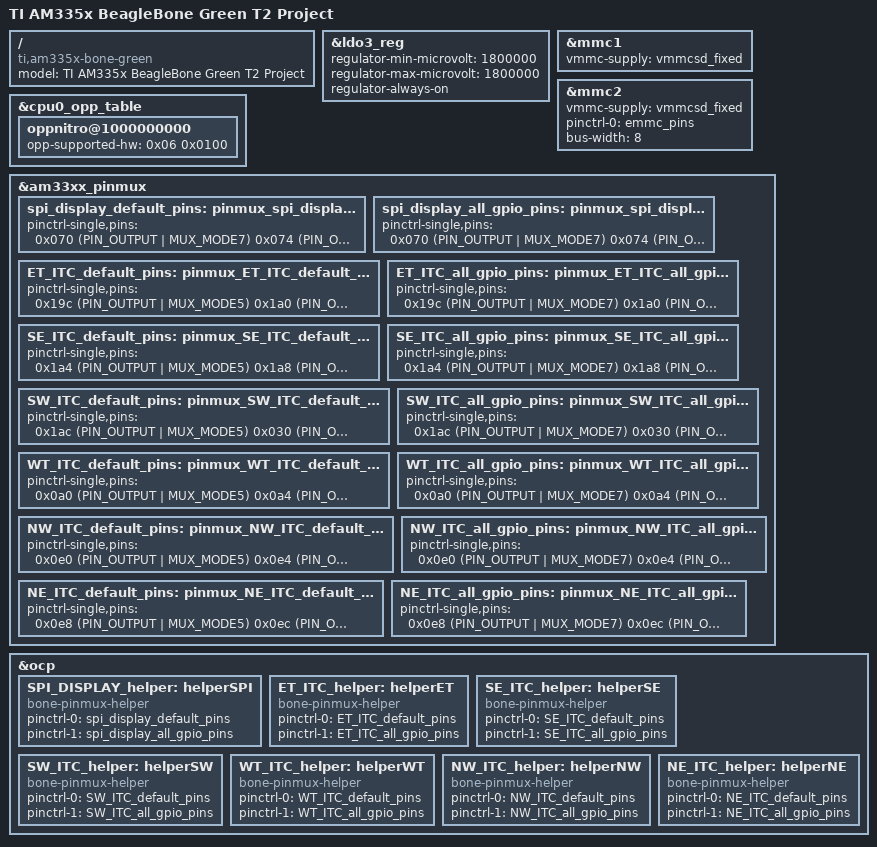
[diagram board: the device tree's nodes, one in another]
/*
 * Base device tree for BeagleBone Green as used in the T2 indefinitely scalable tile
 * 
 * Revisions Copyrignt (C) 2017 The Regents of the University of New Mexico
 * Author: Dave Ackley <ackley@ackleyshack.com>
 *
 * Based on am335x-bonegreen.dts, which is
 * Copyright (C) 2012 Texas Instruments Incorporated - http://www.ti.com/
 *
 * This program is free software; you can redistribute it and/or modify
 * it under the terms of the GNU General Public License version 2 as
 * published by the Free Software Foundation.
 */
/dts-v1/;

#include "am33xx.dtsi"
#include "am335x-bone-common.dtsi"

/* AHAX: 2017-05-19 PRUSS option: For now we are going with UIO.. */
#include "am33xx-pruss-uio.dtsi"

/ {
	model = "TI AM335x BeagleBone Green T2 Project";
	compatible = "ti,am335x-bone-green", "ti,am335x-bone-black", "ti,am335x-bone", "ti,am33xx";
};

&ldo3_reg {
	regulator-min-microvolt = <1800000>;
	regulator-max-microvolt = <1800000>;
	regulator-always-on;
};

&mmc1 {
	vmmc-supply = <&vmmcsd_fixed>;
};

&mmc2 {
	vmmc-supply = <&vmmcsd_fixed>;
	pinctrl-names = "default";
	pinctrl-0 = <&emmc_pins>;
	bus-width = <8>;
	status = "okay";
};

&cpu0_opp_table {
	/*
	 * All PG 2.0 silicon may not support 1GHz but some of the early
	 * BeagleBone Blacks have PG 2.0 silicon which is guaranteed
	 * to support 1GHz OPP so enable it for PG 2.0 on this board.
	 */
	oppnitro@1000000000 {
		opp-supported-hw = <0x06 0x0100>;
	};
};

/****************************************
* Pin Muxing
****************************************/
&am33xx_pinmux {
#if 0
	 // From ebb chp13 overlay sample dts
         pru_pru_pins: pinmux_pru_pru_pins {   // The PRU pin modes
            pinctrl-single,pins = <
               0x1a4 0x05  // P9_27 pr1_pru0_pru_r30_5, MODE5 | OUTPUT | PRU
               0x19c 0x26  // P9_28 pr1_pru0_pru_r31_3, MODE6 | INPUT | PRU
            >;
         };
#endif

	 // SPI DISPLAY SUPPORT VIA SPI0 HARDWARE
         spi_display_default_pins: pinmux_spi_display_default_pins {   
            pinctrl-single,pins = <
	       0x070 (PIN_OUTPUT | MUX_MODE7)        // P9_11  PINS=28  GPIO=30  T2=DSP_PWRON
	       0x074 (PIN_OUTPUT | MUX_MODE7)        // P9_13  PINS=29  GPIO=31  T2=DSP_RESET
	       0x040 (PIN_OUTPUT | MUX_MODE7)        // P9_15  PINS=16  GPIO=48  T2=DSP_DC
	       0x17c (PIN_INPUT_PULLUP | MUX_MODE7)  // P9_19  PINS=95  GPIO=13  T2=TP_IRQ
	       0x178 (PIN_OUTPUT | MUX_MODE7)        // P9_20  PINS=94  GPIO=12  T2=TP_CS
	       0x15c (PIN_OUTPUT | MUX_MODE0)        // P9_17  PINS=87  GPIO=5   T2=SPI0_CS
	       0x158 (PIN_INPUT_PULLUP | MUX_MODE0)  // P9_18  PINS=86  GPIO=4   T2=SPI0_D1
	       0x154 (PIN_OUTPUT | MUX_MODE0)        // P9_21  PINS=85  GPIO=3   T2=SPI0_D0
	       0x150 (PIN_OUTPUT | MUX_MODE0)        // P9_22  PINS=84  GPIO=2   T2=SPI0_SCLK
            >;
         };

	 // SPI DISPLAY SUPPORT ALL GPIOS FOR DEBUGGING
	 spi_display_all_gpio_pins: pinmux_spi_display_all_gpio_pins {   // GPIO pins for linux
            pinctrl-single,pins = <
	       0x070 (PIN_OUTPUT | MUX_MODE7)        // P9_11  PINS=28  GPIO=30  T2=DSP_PWRON
	       0x074 (PIN_OUTPUT | MUX_MODE7)        // P9_13  PINS=29  GPIO=31  T2=DSP_RESET
	       0x040 (PIN_OUTPUT | MUX_MODE7)        // P9_15  PINS=16  GPIO=48  T2=DSP_DC
	       0x17c (PIN_INPUT_PULLUP | MUX_MODE7)  // P9_19  PINS=95  GPIO=13  T2=TP_IRQ
	       0x178 (PIN_OUTPUT | MUX_MODE7)        // P9_20  PINS=94  GPIO=12  T2=TP_CS
	       0x15c (PIN_OUTPUT | MUX_MODE7)        // P9_17  PINS=87  GPIO=5   T2=SPI0_CS as gpio
	       0x158 (PIN_INPUT_PULLUP | MUX_MODE7)  // P9_18  PINS=86  GPIO=4   T2=SPI0_D1 as gpio
	       0x154 (PIN_OUTPUT | MUX_MODE7)        // P9_21  PINS=85  GPIO=3   T2=SPI0_D0 as gpio
	       0x150 (PIN_OUTPUT | MUX_MODE7)        // P9_22  PINS=84  GPIO=2   T2=SPI0_SCLK as gpio
            >;
         };

	 /////////////////
	 // T2 InterTile Connector (ITC) PIN MUXES
	 //
	 // NOTE: Conventional ITC iteration goes clockwise from east: ET,SE,SW,WT,NW,NE
	 // (though that doesn't matter explicitly in any of these .dts declarations).
	 //
	 // NOTE: We have no pullup/downs on any of the {ET,WT,NE,NW,SE,SW}_ITC signal 
	 // pins, because they all connect to line drivers with bus hold circuits.  We
	 // hope that's the right thing to do.

	 // ET_ITC default pins (split PRU/Linux gpio)
         ET_ITC_default_pins: pinmux_ET_ITC_default_pins {
            pinctrl-single,pins = <
               0x19c (PIN_OUTPUT | MUX_MODE5)  // P9_28  PINS=103 GPIO=113 T2=ET_TXRDY pr1_pru0_pru_r30_3
               0x1a0 (PIN_OUTPUT | MUX_MODE5)  // P9_42B PINS=104 GPIO=114 T2=ET_TXDAT pr1_pru0_pru_r30_4
               0x164 (PIN_INPUT  | MUX_MODE7)  // P9_42A PINS=89  GPIO=7   T2=RSRVINP2 (conflicts with ET_TXDAT, must be input)
               0x190 (PIN_INPUT  | MUX_MODE6)  // P9_31  PINS=100 GPIO=110 T2=ET_RXRDY pr1_pru0_pru_r31_0
               0x194 (PIN_INPUT  | MUX_MODE6)  // P9_29  PINS=101 GPIO=111 T2=ET_RXDAT pr1_pru0_pru_r31_1
               0x090 (PIN_OUTPUT | MUX_MODE7)  // P8_07  PINS=36  GPIO=66  T2=ET_ORQLK
               0x094 (PIN_OUTPUT | MUX_MODE7)  // P8_08  PINS=37  GPIO=67  T2=ET_OGRLK
               0x09c (PIN_INPUT  | MUX_MODE7)  // P8_09  PINS=39  GPIO=69  T2=ET_IRQLK
               0x098 (PIN_INPUT  | MUX_MODE7)  // P8_10  PINS=38  GPIO=68  T2=ET_IGRLK
            >;
         };

	 // ET_ITC all gpio pins (Linux gpio)
         ET_ITC_all_gpio_pins: pinmux_ET_ITC_all_gpio_pins {
            pinctrl-single,pins = <
               0x19c (PIN_OUTPUT | MUX_MODE7)  // P9_28  PINS=103 GPIO=113 T2=ET_TXRDY as gpio
               0x1a0 (PIN_OUTPUT | MUX_MODE7)  // P9_42B PINS=104 GPIO=114 T2=ET_TXDAT as gpio
               0x164 (PIN_INPUT  | MUX_MODE7)  // P9_42A PINS=89  GPIO=7   T2=RSRVINP2 (shares pin with ET_TXDAT, must be input)
               0x190 (PIN_INPUT  | MUX_MODE7)  // P9_31  PINS=100 GPIO=110 T2=ET_RXRDY as gpio
               0x194 (PIN_INPUT  | MUX_MODE7)  // P9_29  PINS=101 GPIO=111 T2=ET_RXDAT as gpio
               0x090 (PIN_OUTPUT | MUX_MODE7)  // P8_07  PINS=36  GPIO=66  T2=ET_ORQLK
               0x094 (PIN_OUTPUT | MUX_MODE7)  // P8_08  PINS=37  GPIO=67  T2=ET_OGRLK
               0x09c (PIN_INPUT  | MUX_MODE7)  // P8_09  PINS=39  GPIO=69  T2=ET_IRQLK
               0x098 (PIN_INPUT  | MUX_MODE7)  // P8_10  PINS=38  GPIO=68  T2=ET_IGRLK
            >;
         };


	 // SE_ITC default pins (split PRU/Linux gpio)
         SE_ITC_default_pins: pinmux_SE_ITC_default_pins {
            pinctrl-single,pins = <
               0x1a4 (PIN_OUTPUT | MUX_MODE5)  // P9_27  PINS=106 GPIO=115 T2=SE_TXRDY pr1_pru0_pru_r30_5
               0x1a8 (PIN_OUTPUT | MUX_MODE5)  // P9_41B PINS=?   GPIO=116 T2=SE_TXDAT pr1_pru0_pru_r30_6
               0x1b4 (PIN_INPUT  | MUX_MODE7)  // P9_41A PINS=109 GPIO=20  T2=RSRVINP1 (shares pin with SE_TXDAT, must be input)
               0x198 (PIN_INPUT  | MUX_MODE6)  // P9_30  PINS=102 GPIO=112 T2=SE_RXRDY pr1_pru0_pru_r31_2
               0x038 (PIN_INPUT  | MUX_MODE6)  // P8_16  PINS=43  GPIO=14  T2=SE_RXDAT pr1_pru0_pru_r31_14
               0x034 (PIN_OUTPUT | MUX_MODE7)  // P8_11  PINS=13  GPIO=45  T2=SE_ORQLK
               0x024 (PIN_OUTPUT | MUX_MODE7)  // P8_13  PINS=9   GPIO=23  T2=SE_OGRLK
               0x028 (PIN_INPUT  | MUX_MODE7)  // P8_14  PINS=10  GPIO=26  T2=SE_IRQLK
               0x02c (PIN_INPUT  | MUX_MODE7)  // P8_17  PINS=11  GPIO=27  T2=SE_IGRLK
            >;
         };

	 // SE_ITC all gpio pins (Linux gpio)
         SE_ITC_all_gpio_pins: pinmux_SE_ITC_all_gpio_pins {
            pinctrl-single,pins = <
               0x1a4 (PIN_OUTPUT | MUX_MODE7)  // P9_27  PINS=106 GPIO=115 T2=SE_TXRDY as gpio
               0x1a8 (PIN_OUTPUT | MUX_MODE7)  // P9_41B PINS=?   GPIO=116 T2=SE_TXDAT as gpio
               0x1b4 (PIN_INPUT  | MUX_MODE7)  // P9_41A PINS=109 GPIO=20  T2=RSRVINP1 (shares pin with SE_TXDAT, must be input)
               0x198 (PIN_INPUT  | MUX_MODE7)  // P9_30  PINS=102 GPIO=112 T2=SE_RXRDY as gpio
               0x038 (PIN_INPUT  | MUX_MODE7)  // P8_16  PINS=43  GPIO=14  T2=SE_RXDAT as gpio
               0x034 (PIN_OUTPUT | MUX_MODE7)  // P8_11  PINS=13  GPIO=45  T2=SE_ORQLK
               0x024 (PIN_OUTPUT | MUX_MODE7)  // P8_13  PINS=9   GPIO=23  T2=SE_OGRLK
               0x028 (PIN_INPUT  | MUX_MODE7)  // P8_14  PINS=10  GPIO=26  T2=SE_IRQLK
               0x02c (PIN_INPUT  | MUX_MODE7)  // P8_17  PINS=11  GPIO=27  T2=SE_IGRLK
            >;
         };

	 // SW_ITC default pins (split PRU/Linux gpio)
         SW_ITC_default_pins: pinmux_SW_ITC_default_pins {
            pinctrl-single,pins = <
               0x1ac (PIN_OUTPUT | MUX_MODE5)  // P9_25  PINS=107 GPIO=117 T2=SW_TXRDY pr1_pru0_pru_r30_7
               0x030 (PIN_OUTPUT | MUX_MODE5)  // P8_12  PINS=12  GPIO=44  T2=SW_TXDAT pr1_pru0_pru_r30_14
               0x03c (PIN_INPUT  | MUX_MODE6)  // P8_15  PINS=15  GPIO=47  T2=SW_RXRDY pr1_pru0_pru_r31_15
               0x184 (PIN_INPUT  | MUX_MODE6)  // P9_24  PINS=96  GPIO=15  T2=SW_RXDAT pr1_pru0_pru_r31_16
               0x08c (PIN_OUTPUT | MUX_MODE7)  // P8_18  PINS=35  GPIO=65  T2=SW_ORQLK
               0x024 (PIN_OUTPUT | MUX_MODE7)  // P8_19  PINS=8   GPIO=22  T2=SW_OGRLK
               0x07c (PIN_INPUT  | MUX_MODE7)  // P8_26  PINS=31  GPIO=61  T2=SW_IRQLK
               0x0d8 (PIN_INPUT  | MUX_MODE7)  // P8_31  PINS=54  GPIO=10  T2=SW_IGRLK
            >;
         };

	 // SW_ITC all gpio pins (Linux gpio)
         SW_ITC_all_gpio_pins: pinmux_SW_ITC_all_gpio_pins {
            pinctrl-single,pins = <
               0x1ac (PIN_OUTPUT | MUX_MODE7)  // P9_25  PINS=107 GPIO=117 T2=SW_TXRDY as gpio
               0x030 (PIN_OUTPUT | MUX_MODE7)  // P8_12  PINS=12  GPIO=44  T2=SW_TXDAT as gpio
               0x03c (PIN_INPUT  | MUX_MODE7)  // P8_15  PINS=15  GPIO=47  T2=SW_RXRDY as gpio
               0x184 (PIN_INPUT  | MUX_MODE7)  // P9_24  PINS=96  GPIO=15  T2=SW_RXDAT as gpio
               0x08c (PIN_OUTPUT | MUX_MODE7)  // P8_18  PINS=35  GPIO=65  T2=SW_ORQLK
               0x024 (PIN_OUTPUT | MUX_MODE7)  // P8_19  PINS=8   GPIO=22  T2=SW_OGRLK
               0x07c (PIN_INPUT  | MUX_MODE7)  // P8_26  PINS=31  GPIO=61  T2=SW_IRQLK
               0x0d8 (PIN_INPUT  | MUX_MODE7)  // P8_31  PINS=54  GPIO=10  T2=SW_IGRLK
            >;
         };

	 // WT_ITC default pins (split PRU/Linux gpio)
         WT_ITC_default_pins: pinmux_WT_ITC_default_pins {
            pinctrl-single,pins = <
               0x0a0 (PIN_OUTPUT | MUX_MODE5)  // P8_45  PINS=40  GPIO=70  T2=WT_TXRDY pr1_pru1_pru_r30_0
               0x0a4 (PIN_OUTPUT | MUX_MODE5)  // P8_46  PINS=41  GPIO=71  T2=WT_TXDAT pr1_pru1_pru_r30_1
               0x0b8 (PIN_INPUT  | MUX_MODE6)  // P8_39  PINS=46  GPIO=76  T2=WT_RXRDY pr1_pru1_pru_r31_6
               0x0bc (PIN_INPUT  | MUX_MODE6)  // P8_40  PINS=47  GPIO=77  T2=WT_RXDAT pr1_pru1_pru_r31_7
               0x0dc (PIN_OUTPUT | MUX_MODE7)  // P8_32  PINS=55  GPIO=11  T2=WT_ORQLK
               0x0d4 (PIN_OUTPUT | MUX_MODE7)  // P8_33  PINS=53  GPIO=9   T2=WT_OGRLK
               0x0cc (PIN_INPUT  | MUX_MODE7)  // P8_34  PINS=51  GPIO=81  T2=WT_IRQLK
               0x0d0 (PIN_INPUT  | MUX_MODE7)  // P8_35  PINS=52  GPIO=8   T2=WT_IGRLK
            >;
         };

	 // WT_ITC all gpio pins (Linux gpio)
         WT_ITC_all_gpio_pins: pinmux_WT_ITC_all_gpio_pins {
            pinctrl-single,pins = <
               0x0a0 (PIN_OUTPUT | MUX_MODE7)  // P8_45  PINS=40  GPIO=70  T2=WT_TXRDY as gpio
               0x0a4 (PIN_OUTPUT | MUX_MODE7)  // P8_46  PINS=41  GPIO=71  T2=WT_TXDAT as gpio
               0x0b8 (PIN_INPUT  | MUX_MODE7)  // P8_39  PINS=46  GPIO=76  T2=WT_RXRDY as gpio
               0x0bc (PIN_INPUT  | MUX_MODE7)  // P8_40  PINS=47  GPIO=77  T2=WT_RXDAT as gpio
               0x0dc (PIN_OUTPUT | MUX_MODE7)  // P8_32  PINS=55  GPIO=11  T2=WT_ORQLK
               0x0d4 (PIN_OUTPUT | MUX_MODE7)  // P8_33  PINS=53  GPIO=9   T2=WT_OGRLK
               0x0cc (PIN_INPUT  | MUX_MODE7)  // P8_34  PINS=51  GPIO=81  T2=WT_IRQLK
               0x0d0 (PIN_INPUT  | MUX_MODE7)  // P8_35  PINS=52  GPIO=8   T2=WT_IGRLK
            >;
         };

	 // NW_ITC default pins (split PRU/Linux gpio)
         NW_ITC_default_pins: pinmux_NW_ITC_default_pins {
            pinctrl-single,pins = <
               0x0e0 (PIN_OUTPUT | MUX_MODE5)  // P8_27  PINS=56  GPIO=86  T2=NW_TXRDY pr1_pru1_pru_r30_8
               0x0e4 (PIN_OUTPUT | MUX_MODE5)  // P8_39  PINS=57  GPIO=87  T2=NW_TXDAT pr1_pru1_pru_r30_9
               0x0a8 (PIN_INPUT  | MUX_MODE6)  // P8_43  PINS=42  GPIO=72  T2=NW_RXRDY pr1_pru1_pru_r31_2
               0x1ac (PIN_INPUT  | MUX_MODE6)  // P8_44  PINS=43  GPIO=73  T2=NW_RXDAT pr1_pru1_pru_r31_3
               0x0c8 (PIN_OUTPUT | MUX_MODE7)  // P8_36  PINS=50  GPIO=80  T2=NW_ORQLK
               0x0c0 (PIN_OUTPUT | MUX_MODE7)  // P8_37  PINS=48  GPIO=78  T2=NW_OGRLK
               0x0c4 (PIN_INPUT  | MUX_MODE7)  // P8_38  PINS=49  GPIO=79  T2=NW_IRQLK
               0x078 (PIN_INPUT  | MUX_MODE7)  // P9_12  PINS=30  GPIO=60  T2=NW_IGRLK
            >;
         };

	 // NW_ITC all gpio pins (Linux gpio)
         NW_ITC_all_gpio_pins: pinmux_NW_ITC_all_gpio_pins {
            pinctrl-single,pins = <
               0x0e0 (PIN_OUTPUT | MUX_MODE7)  // P8_27  PINS=56  GPIO=86  T2=NW_TXRDY as gpio
               0x0e4 (PIN_OUTPUT | MUX_MODE7)  // P8_39  PINS=57  GPIO=87  T2=NW_TXDAT as gpio
               0x0a8 (PIN_INPUT  | MUX_MODE7)  // P8_43  PINS=42  GPIO=72  T2=NW_RXRDY as gpio
               0x1ac (PIN_INPUT  | MUX_MODE7)  // P8_44  PINS=43  GPIO=73  T2=NW_RXDAT as gpio
               0x0c8 (PIN_OUTPUT | MUX_MODE7)  // P8_36  PINS=50  GPIO=80  T2=NW_ORQLK
               0x0c0 (PIN_OUTPUT | MUX_MODE7)  // P8_37  PINS=48  GPIO=78  T2=NW_OGRLK
               0x0c4 (PIN_INPUT  | MUX_MODE7)  // P8_38  PINS=49  GPIO=79  T2=NW_IRQLK
               0x078 (PIN_INPUT  | MUX_MODE7)  // P9_12  PINS=30  GPIO=60  T2=NW_IGRLK
            >;
         };

	 // NE_ITC default pins (split PRU/Linux gpio)
         NE_ITC_default_pins: pinmux_NE_ITC_default_pins {
            pinctrl-single,pins = <
               0x0e8 (PIN_OUTPUT | MUX_MODE5)  // P8_28  PINS=58  GPIO=88  T2=NE_TXRDY pr1_pru1_pru_r30_10
               0x0ec (PIN_OUTPUT | MUX_MODE5)  // P8_30  PINS=59  GPIO=89  T2=NE_TXDAT pr1_pru1_pru_r30_11
               0x0b0 (PIN_INPUT  | MUX_MODE6)  // P8_41  PINS=44  GPIO=74  T2=NE_RXRDY pr1_pru1_pru_r31_4
               0x0b4 (PIN_INPUT  | MUX_MODE6)  // P8_42  PINS=45  GPIO=75  T2=NE_RXDAT pr1_pru1_pru_r31_5
               0x048 (PIN_OUTPUT | MUX_MODE7)  // P9_14  PINS=18  GPIO=50  T2=NE_ORQLK
               0x04c (PIN_OUTPUT | MUX_MODE7)  // P9_16  PINS=19  GPIO=51  T2=NE_OGRLK
               0x044 (PIN_INPUT  | MUX_MODE7)  // P9_23  PINS=17  GPIO=49  T2=NE_IRQLK
               0x180 (PIN_INPUT  | MUX_MODE7)  // P9_26  PINS=96  GPIO=14  T2=NE_IGRLK
            >;
         };

	 // NE_ITC all gpio pins (Linux gpio)
         NE_ITC_all_gpio_pins: pinmux_NE_ITC_all_gpio_pins {
            pinctrl-single,pins = <
               0x0e8 (PIN_OUTPUT | MUX_MODE7)  // P8_28  PINS=58  GPIO=88  T2=NE_TXRDY as gpio
               0x0ec (PIN_OUTPUT | MUX_MODE7)  // P8_30  PINS=59  GPIO=89  T2=NE_TXDAT as gpio
               0x0b0 (PIN_INPUT  | MUX_MODE7)  // P8_41  PINS=44  GPIO=74  T2=NE_RXRDY as gpio
               0x0b4 (PIN_INPUT  | MUX_MODE7)  // P8_42  PINS=45  GPIO=75  T2=NE_RXDAT as gpio
               0x048 (PIN_OUTPUT | MUX_MODE7)  // P9_14  PINS=18  GPIO=50  T2=NE_ORQLK
               0x04c (PIN_OUTPUT | MUX_MODE7)  // P9_16  PINS=19  GPIO=51  T2=NE_OGRLK
               0x044 (PIN_INPUT  | MUX_MODE7)  // P9_23  PINS=17  GPIO=49  T2=NE_IRQLK
               0x180 (PIN_INPUT  | MUX_MODE7)  // P9_26  PINS=96  GPIO=14  T2=NE_IGRLK
            >;
         };


// P9_11_default_pin: pinmux_P9_11_default_pin {
	// 	pinctrl-single,pins = <0x070  0x36>; };     /* Mode 6 uart */
	// P9_11_gpio_pin: pinmux_P9_11_gpio_pin {
	// 	pinctrl-single,pins = <0x070  0x2F>; };     /* Mode 7, RxActive */


	// A15_spi_pin: pinmux_A15_spi_pin {
	// 	pinctrl-single,pins = <
	// 		BLUE_IO(108, PIN_INPUT_PULLUP | MUX_MODE4) /* spi1_cs1 */
	// 	>;
	// };

	// mux_helper_pins: pins {
	// 	pinctrl-single,pins = <
	// 		/* PRU encoder input */
	// 		0x03c 0x36	/* P8_15,PRU0_r31_15,MODE6 */
	// 		0x038 0x36	/* P8_16,PRU0_r31_16,MODE6 */

	// 		/* PRU Servo output */
	// 		0x0e0 0x25	/*pru1_pru_r30_8, MODE5*/
	// 		0x0e8 0x25	/*pru1_pru_r30_10, MODE5 */
	// 		0x0e4 0x25	/*pr1_pru1_pru_r30_9, MODE5 */
	// 		0x0ec 0x25	/*pru1_pru_r30_11, MODE5 */
	// 		0x0b8 0x25	/*pru1_pru_r30_6, MODE5 */
	// 		0x0bc 0x25	/*pru1_pru_r30_7, MODE5 */
	// 		0x0b0 0x25	/*pru1_pru_r30_4, MODE5 */
	// 		0x0b4 0x25	/*pru1_pru_r30_5, MODE5 */

	// 		/* GPIO Inputs */
	// 		0x09c 0x37	/*P8.9  Pause BUTTON, input pullup*/
	// 		0x098 0x37	/*P8.10 MODE BUTTON input pullup*/
	// 		0x1AC 0x37	/*P9.25 MPU-9150 INTERRUPT IN*/

	// 		/* GPIO Outputs
	// 		0x090 0x0F	/*P8.7 - R7*/
	// 		0x094 0x0F	/*P8.8*/
	// 		0x028 0x0F	/*P8.14*/
	// 		0x02C 0x0F	/*P8.17*/
	// 		0x08c 0x0F	/*P8.18*/
	// 		0x07c 0x0F	/*P8.26*/
	// 		/* 0x0?? 0x0F	/*P8.32 - T5 - BATT_LED3 */
	// 		0x0cc 0x0F	/*P8.34*/
	// 		0x0C8 0x0F	/*P8.36*/
	// 		0x0a8 0x0F	/*P8.43*/
	// 		0x0ac 0x0F	/*P8.44*/
	// 		0x0a0 0x0F	/*P8.45*/
	// 		0x0a4 0x0F	/*P8.46*/
	// 		0x078 0x0F	/*P9.12*/
	// 		0x074 0x0F	/*P9.13*/
	// 		0x040 0x0F	/*P9.15*/
	// 		0x044 0x0F	/*P9.23*/
	// 		0x1b4 0x0F	/*P9.41*/
	// 	>;
	// };

	// /****************************************/
	// /* DSM2 UART4 pinmux                    */
	// /* only pin that swaps between GPIO&UART*/
	// /****************************************/
	// P9_11_default_pin: pinmux_P9_11_default_pin {
	// 	pinctrl-single,pins = <0x070  0x36>; };     /* Mode 6 uart */
	// P9_11_gpio_pin: pinmux_P9_11_gpio_pin {
	// 	pinctrl-single,pins = <0x070  0x2F>; };     /* Mode 7, RxActive */
	// P9_11_gpio_pu_pin: pinmux_P9_11_gpio_pu_pin {
	// 	pinctrl-single,pins = <0x070  0x37>; };     /* Mode 7, Pull-Up, RxActive */
	// P9_11_gpio_pd_pin: pinmux_P9_11_gpio_pd_pin {
	// 	pinctrl-single,pins = <0x070  0x27>; };     /* Mode 7, Pull-Down, RxActive */
	// P9_11_uart_pin: pinmux_P9_11_uart_pin {
	// 	pinctrl-single,pins = <0x070  0x36>; };     /* Mode 6, uart */
};

&ocp {
#if 0  /* Now handled via the ITC groups? */
      pruss {
         pinctrl-names = "default";
         pinctrl-0 = <&pru_pru_pins>;
      };
#endif

      /****************************************
       * activates the pinmux helper list of pin modes
       * I HAVE NO IDEA WHAT THIS ACTUALLY DOES IF ANYTHING HALP
       ****************************************/
/* SWITCHING TO GPIO TEST FOR NOW 6/1/17
        test_helper: helper {
		compatible = "bone-pinmux-helper";
		pinctrl-names = "default";
		pinctrl-0 = <&pru_pru_pins>;
		status = "okay";
       };
*/
        SPI_DISPLAY_helper: helperSPI {
		compatible = "bone-pinmux-helper";
		pinctrl-names = "default", "gpio";
		pinctrl-0 = <&spi_display_default_pins>;
		pinctrl-1 = <&spi_display_all_gpio_pins>;
		status = "okay";
       };

       ET_ITC_helper: helperET {
		compatible = "bone-pinmux-helper";
		pinctrl-names = "default", "gpio";
		pinctrl-0 = <&ET_ITC_default_pins>;
		pinctrl-1 = <&ET_ITC_all_gpio_pins>;
		status = "okay";
       };

       SE_ITC_helper: helperSE {
		compatible = "bone-pinmux-helper";
		pinctrl-names = "default", "gpio";
		pinctrl-0 = <&SE_ITC_default_pins>;
		pinctrl-1 = <&SE_ITC_all_gpio_pins>;
		status = "okay";
       };

       SW_ITC_helper: helperSW {
		compatible = "bone-pinmux-helper";
		pinctrl-names = "default", "gpio";
		pinctrl-0 = <&SW_ITC_default_pins>;
		pinctrl-1 = <&SW_ITC_all_gpio_pins>;
		status = "okay";
       };

       WT_ITC_helper: helperWT {
		compatible = "bone-pinmux-helper";
		pinctrl-names = "default", "gpio";
		pinctrl-0 = <&WT_ITC_default_pins>;
		pinctrl-1 = <&WT_ITC_all_gpio_pins>;
		status = "okay";
       };

       NW_ITC_helper: helperNW {
		compatible = "bone-pinmux-helper";
		pinctrl-names = "default", "gpio";
		pinctrl-0 = <&NW_ITC_default_pins>;
		pinctrl-1 = <&NW_ITC_all_gpio_pins>;
		status = "okay";
       };

       NE_ITC_helper: helperNE {
		compatible = "bone-pinmux-helper";
		pinctrl-names = "default", "gpio";
		pinctrl-0 = <&NE_ITC_default_pins>;
		pinctrl-1 = <&NE_ITC_all_gpio_pins>;
		status = "okay";
       };

	// /****************************************
	//  * configurable DSM2 pin swaps between GPIO & UART4 at runtime
	//  ****************************************/
	// P9_11_pinmux {
	// 	compatible = "bone-pinmux-helper";
	// 	status = "okay";
	// 	pinctrl-names = "default", "gpio", "gpio_pu", "gpio_pd", "uart";

	// 	pinctrl-0 = <&P9_11_default_pin>;
	// 	pinctrl-1 = <&P9_11_gpio_pin>;
	// 	pinctrl-2 = <&P9_11_gpio_pu_pin>;
	// 	pinctrl-3 = <&P9_11_gpio_pd_pin>;
	// 	pinctrl-4 = <&P9_11_uart_pin>;
	// };
};


